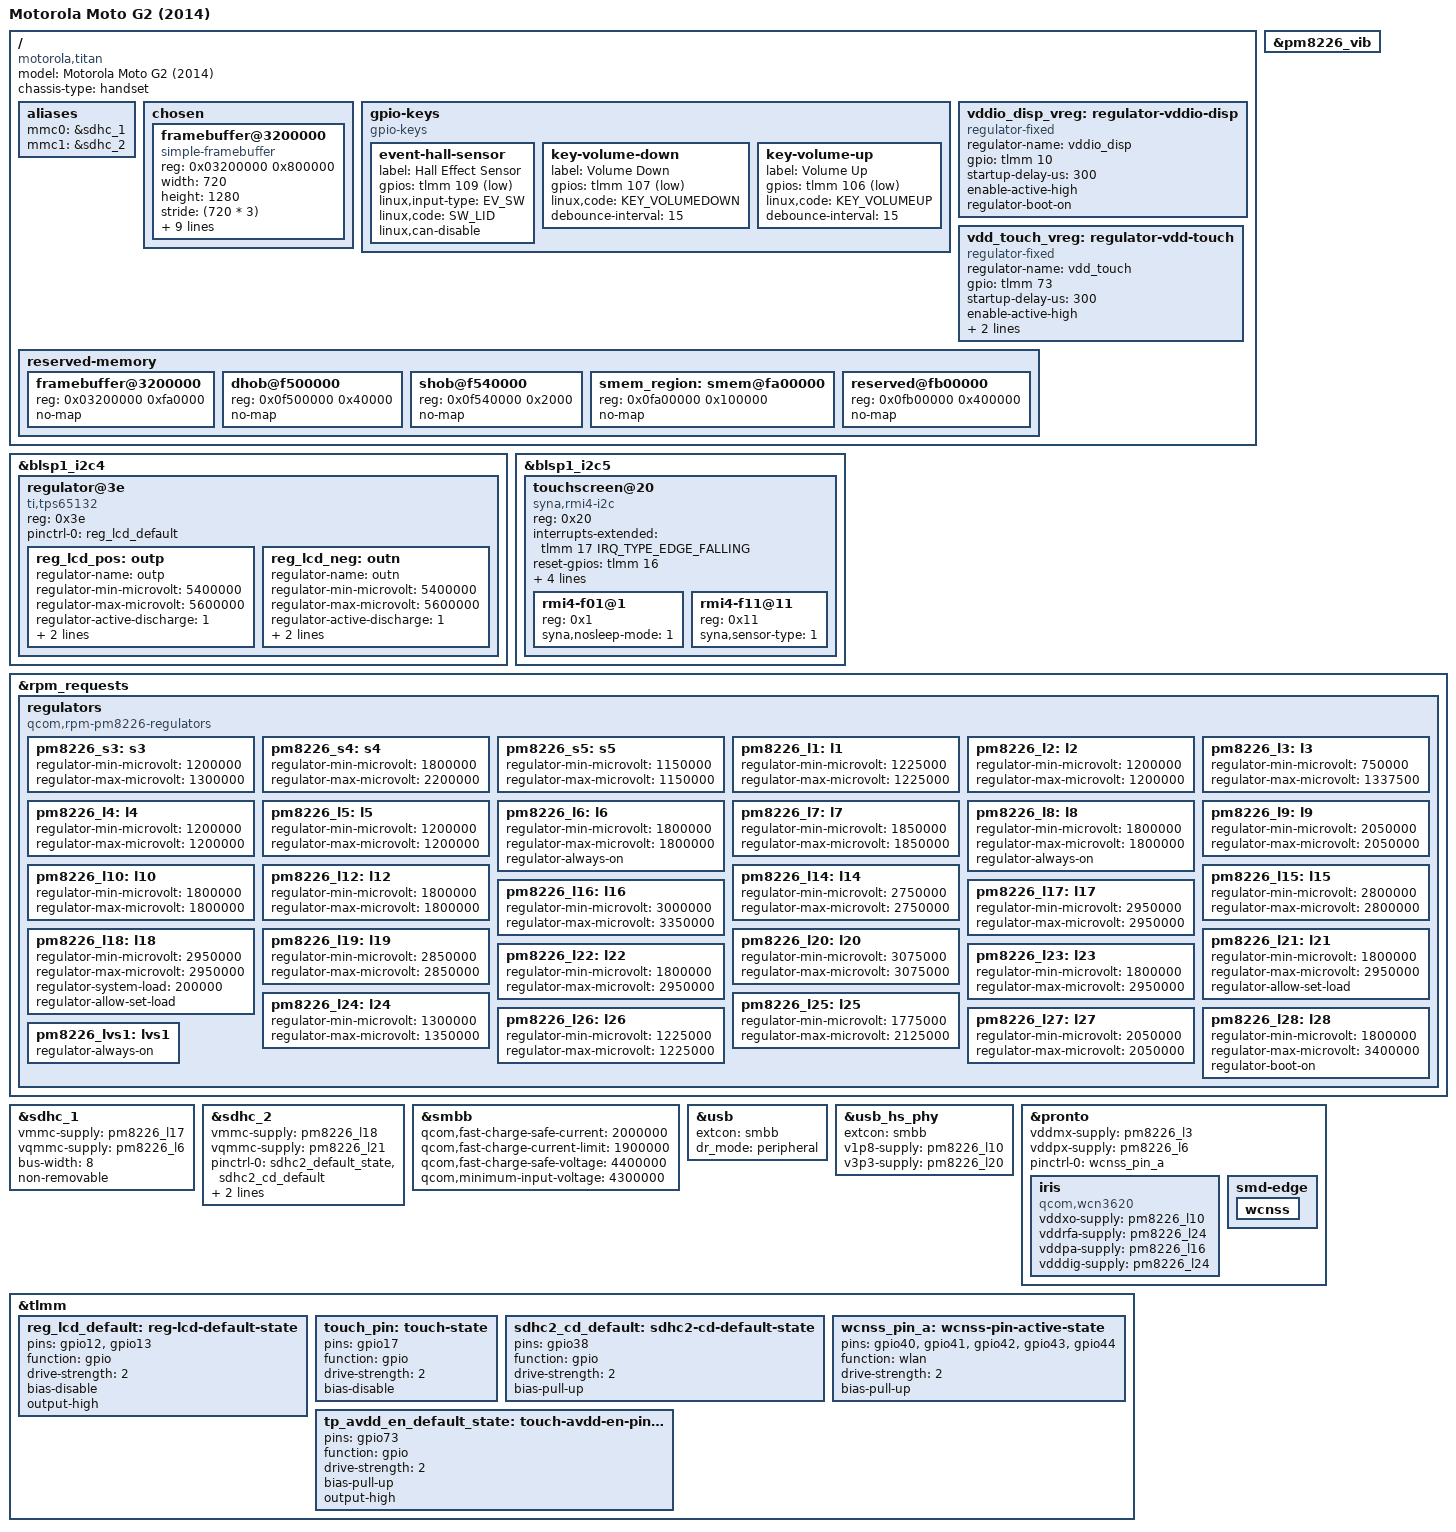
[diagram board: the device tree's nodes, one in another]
// SPDX-License-Identifier: BSD-3-Clause
/*
 * Copyright (c) 2026, David Wales <daviewales@disroot.org>
 */

/dts-v1/;

#include "qcom-msm8226.dtsi"
#include "pm8226.dtsi"

/delete-node/ &smem_region;

/ {
	model = "Motorola Moto G2 (2014)";
	compatible = "motorola,titan", "qcom,msm8226";
	chassis-type = "handset";

	aliases {
		mmc0 = &sdhc_1; /* eMMC */
		mmc1 = &sdhc_2; /* SD card */
	};

	chosen {
		#address-cells = <1>;
		#size-cells = <1>;
		ranges;

		framebuffer@3200000 {
			compatible = "simple-framebuffer";
			reg = <0x03200000 0x800000>;
			width = <720>;
			height = <1280>;
			stride = <(720 * 3)>;
			format = "r8g8b8";
			vsp-supply = <&reg_lcd_pos>;
			vsn-supply = <&reg_lcd_neg>;
			vddio-supply = <&vddio_disp_vreg>;

			clocks = <&mmcc MDSS_AHB_CLK>,
				 <&mmcc MDSS_AXI_CLK>,
				 <&mmcc MDSS_BYTE0_CLK>,
				 <&mmcc MDSS_ESC0_CLK>,
				 <&mmcc MDSS_MDP_CLK>,
				 <&mmcc MMSS_MISC_AHB_CLK>,
				 <&mmcc MDSS_PCLK0_CLK>,
				 <&mmcc MDSS_VSYNC_CLK>;
			power-domains = <&mmcc MDSS_GDSC>;
		};
	};

	gpio-keys {
		compatible = "gpio-keys";

		event-hall-sensor {
			label = "Hall Effect Sensor";
			gpios = <&tlmm 109 GPIO_ACTIVE_LOW>;
			linux,input-type = <EV_SW>;
			linux,code = <SW_LID>;
			linux,can-disable;
		};

		key-volume-down {
			label = "Volume Down";
			gpios = <&tlmm 107 GPIO_ACTIVE_LOW>;
			linux,code = <KEY_VOLUMEDOWN>;
			debounce-interval = <15>;
		};

		key-volume-up {
			label = "Volume Up";
			gpios = <&tlmm 106 GPIO_ACTIVE_LOW>;
			linux,code = <KEY_VOLUMEUP>;
			debounce-interval = <15>;
		};
	};

	vddio_disp_vreg: regulator-vddio-disp {
		compatible = "regulator-fixed";
		regulator-name = "vddio_disp";

		gpio = <&tlmm 10 GPIO_ACTIVE_HIGH>;
		startup-delay-us = <300>;
		enable-active-high;
		regulator-boot-on;
	};

	vdd_touch_vreg: regulator-vdd-touch {
		compatible = "regulator-fixed";
		regulator-name = "vdd_touch";

		gpio = <&tlmm 73 GPIO_ACTIVE_HIGH>;
		startup-delay-us = <300>;
		enable-active-high;
		regulator-pull-down;

		pinctrl-0 = <&tp_avdd_en_default_state>;
		pinctrl-names = "default";
	};

	reserved-memory {
		#address-cells = <1>;
		#size-cells = <1>;
		ranges;

		framebuffer@3200000 {
			reg = <0x03200000 0xfa0000>;
			no-map;
		};

		dhob@f500000 {
			reg = <0x0f500000 0x40000>;
			no-map;
		};

		shob@f540000 {
			reg = <0x0f540000 0x2000>;
			no-map;
		};

		smem_region: smem@fa00000 {
			reg = <0x0fa00000 0x100000>;
			no-map;
		};

		reserved@fb00000 {
			reg = <0x0fb00000 0x400000>;
			no-map;
		};
	};
};

&blsp1_i2c4 {
	status = "okay";

	regulator@3e {
		compatible = "ti,tps65132";
		reg = <0x3e>;

		pinctrl-0 = <&reg_lcd_default>;
		pinctrl-names = "default";

		reg_lcd_pos: outp {
			regulator-name = "outp";
			regulator-min-microvolt = <5400000>;
			regulator-max-microvolt = <5600000>;
			regulator-active-discharge = <1>;
			regulator-boot-on;
			enable-gpios = <&tlmm 12 GPIO_ACTIVE_HIGH>;
		};

		reg_lcd_neg: outn {
			regulator-name = "outn";
			regulator-min-microvolt = <5400000>;
			regulator-max-microvolt = <5600000>;
			regulator-active-discharge = <1>;
			regulator-boot-on;
			enable-gpios = <&tlmm 13 GPIO_ACTIVE_HIGH>;
		};
	};
};

&blsp1_i2c5 {
	status = "okay";

	touchscreen@20 {
		compatible = "syna,rmi4-i2c";
		reg = <0x20>;

		interrupts-extended = <&tlmm 17 IRQ_TYPE_EDGE_FALLING>;
		reset-gpios = <&tlmm 16 (GPIO_ACTIVE_HIGH | GPIO_PULL_UP)>;

		vdd-supply = <&vdd_touch_vreg>;
		vio-supply = <&pm8226_lvs1>;

		pinctrl-0 = <&touch_pin>;
		pinctrl-names = "default";

		syna,startup-delay-ms = <100>;

		#address-cells = <1>;
		#size-cells = <0>;

		rmi4-f01@1 {
			reg = <0x1>;
			syna,nosleep-mode = <1>;
		};

		rmi4-f11@11 {
			reg = <0x11>;
			syna,sensor-type = <1>;
		};
	};
};

&pm8226_vib {
	status = "okay";
};

&rpm_requests {
	regulators {
		compatible = "qcom,rpm-pm8226-regulators";

		pm8226_s3: s3 {
			regulator-min-microvolt = <1200000>;
			regulator-max-microvolt = <1300000>;
		};

		pm8226_s4: s4 {
			regulator-min-microvolt = <1800000>;
			regulator-max-microvolt = <2200000>;
		};

		pm8226_s5: s5 {
			regulator-min-microvolt = <1150000>;
			regulator-max-microvolt = <1150000>;
		};

		pm8226_l1: l1 {
			regulator-min-microvolt = <1225000>;
			regulator-max-microvolt = <1225000>;
		};

		pm8226_l2: l2 {
			regulator-min-microvolt = <1200000>;
			regulator-max-microvolt = <1200000>;
		};

		pm8226_l3: l3 {
			regulator-min-microvolt = <750000>;
			regulator-max-microvolt = <1337500>;
		};

		pm8226_l4: l4 {
			regulator-min-microvolt = <1200000>;
			regulator-max-microvolt = <1200000>;
		};

		pm8226_l5: l5 {
			regulator-min-microvolt = <1200000>;
			regulator-max-microvolt = <1200000>;
		};

		pm8226_l6: l6 {
			/* Hall effect sensor */
			regulator-min-microvolt = <1800000>;
			regulator-max-microvolt = <1800000>;
			regulator-always-on;
		};

		pm8226_l7: l7 {
			regulator-min-microvolt = <1850000>;
			regulator-max-microvolt = <1850000>;
		};

		pm8226_l8: l8 {
			regulator-min-microvolt = <1800000>;
			regulator-max-microvolt = <1800000>;
			regulator-always-on;
		};

		pm8226_l9: l9 {
			regulator-min-microvolt = <2050000>;
			regulator-max-microvolt = <2050000>;
		};

		pm8226_l10: l10 {
			regulator-min-microvolt = <1800000>;
			regulator-max-microvolt = <1800000>;
		};

		pm8226_l12: l12 {
			regulator-min-microvolt = <1800000>;
			regulator-max-microvolt = <1800000>;
		};

		pm8226_l14: l14 {
			regulator-min-microvolt = <2750000>;
			regulator-max-microvolt = <2750000>;
		};

		pm8226_l15: l15 {
			regulator-min-microvolt = <2800000>;
			regulator-max-microvolt = <2800000>;
		};

		pm8226_l16: l16 {
			regulator-min-microvolt = <3000000>;
			regulator-max-microvolt = <3350000>;
		};

		pm8226_l17: l17 {
			regulator-min-microvolt = <2950000>;
			regulator-max-microvolt = <2950000>;
		};

		pm8226_l18: l18 {
			regulator-min-microvolt = <2950000>;
			regulator-max-microvolt = <2950000>;
			regulator-system-load = <200000>;
			regulator-allow-set-load;
		};

		pm8226_l19: l19 {
			regulator-min-microvolt = <2850000>;
			regulator-max-microvolt = <2850000>;
		};

		pm8226_l20: l20 {
			regulator-min-microvolt = <3075000>;
			regulator-max-microvolt = <3075000>;
		};

		pm8226_l21: l21 {
			regulator-min-microvolt = <1800000>;
			regulator-max-microvolt = <2950000>;
			regulator-allow-set-load;
		};

		pm8226_l22: l22 {
			regulator-min-microvolt = <1800000>;
			regulator-max-microvolt = <2950000>;
		};

		pm8226_l23: l23 {
			regulator-min-microvolt = <1800000>;
			regulator-max-microvolt = <2950000>;
		};

		pm8226_l24: l24 {
			regulator-min-microvolt = <1300000>;
			regulator-max-microvolt = <1350000>;
		};

		pm8226_l25: l25 {
			regulator-min-microvolt = <1775000>;
			regulator-max-microvolt = <2125000>;
		};

		pm8226_l26: l26 {
			regulator-min-microvolt = <1225000>;
			regulator-max-microvolt = <1225000>;
		};

		pm8226_l27: l27 {
			regulator-min-microvolt = <2050000>;
			regulator-max-microvolt = <2050000>;
		};

		pm8226_l28: l28 {
			regulator-min-microvolt = <1800000>;
			regulator-max-microvolt = <3400000>;
			regulator-boot-on;
		};

		pm8226_lvs1: lvs1 {
			/* Pull-up for I2C lines */
			regulator-always-on;
		};
	};
};

&sdhc_1 {
	vmmc-supply = <&pm8226_l17>;
	vqmmc-supply = <&pm8226_l6>;
	bus-width = <8>;
	non-removable;

	status = "okay";
};

&sdhc_2 {
	vmmc-supply = <&pm8226_l18>;
	vqmmc-supply = <&pm8226_l21>;
	pinctrl-0 = <&sdhc2_default_state &sdhc2_cd_default>;
	pinctrl-names = "default";
	cd-gpios = <&tlmm 38 GPIO_ACTIVE_LOW>;
	bus-width = <4>;

	status = "okay";
};

&smbb {
	qcom,fast-charge-safe-current = <2000000>;
	qcom,fast-charge-current-limit = <1900000>;
	qcom,fast-charge-safe-voltage = <4400000>;
	qcom,minimum-input-voltage = <4300000>;

	status = "okay";
};

&usb {
	extcon = <&smbb>;
	dr_mode = "peripheral";

	status = "okay";
};

&usb_hs_phy {
	extcon = <&smbb>;
	v1p8-supply = <&pm8226_l10>;
	v3p3-supply = <&pm8226_l20>;
};

&pronto {
	vddmx-supply = <&pm8226_l3>;
	vddpx-supply = <&pm8226_l6>;

	pinctrl-names = "default";
	pinctrl-0 = <&wcnss_pin_a>;

	status = "okay";

	iris {
		compatible = "qcom,wcn3620";
		vddxo-supply = <&pm8226_l10>;
		vddrfa-supply = <&pm8226_l24>;
		vddpa-supply = <&pm8226_l16>;
		vdddig-supply = <&pm8226_l24>;
	};

	smd-edge {
		wcnss {
			status = "okay";
		};
	};
};

&tlmm {
	reg_lcd_default: reg-lcd-default-state {
		pins = "gpio12", "gpio13";
		function = "gpio";
		drive-strength = <2>;
		bias-disable;
		output-high;
	};

	touch_pin: touch-state {
		pins = "gpio17";
		function = "gpio";

		drive-strength = <2>;
		bias-disable;
	};

	sdhc2_cd_default: sdhc2-cd-default-state {
		pins = "gpio38";
		function = "gpio";
		drive-strength = <2>;
		bias-pull-up;
	};

	wcnss_pin_a: wcnss-pin-active-state {
		pins =  "gpio40", "gpio41", "gpio42", "gpio43", "gpio44";
		function = "wlan";
		drive-strength = <2>;
		bias-pull-up;
	};

	tp_avdd_en_default_state: touch-avdd-en-pin-default-state {
		pins = "gpio73";
		function = "gpio";
		drive-strength = <2>;
		bias-pull-up;
		output-high;
	};
};
